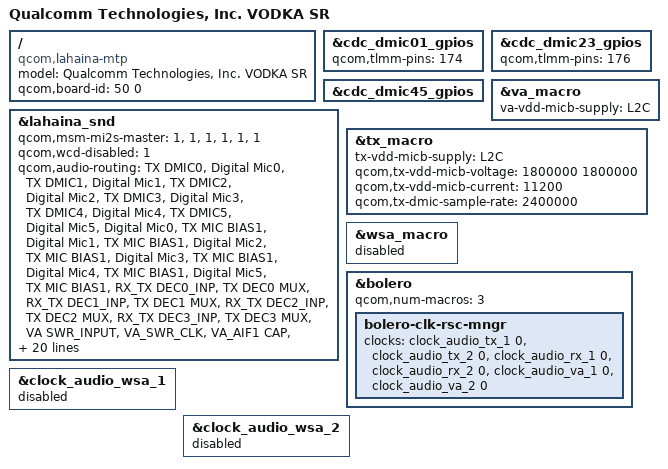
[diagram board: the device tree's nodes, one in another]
/dts-v1/;
/plugin/;

#include "VODKA-EVB2-overlay.dts"

/ {
	model = "Qualcomm Technologies, Inc. VODKA SR";
	compatible = "qcom,lahaina-mtp", "qcom,lahaina", "qcom,mtp";
	qcom,board-id = <50 0>;
};

/*   ====================================
*    overlay for display - start
*    ====================================
*/

/*   ====================================
*    overlay for display - end
*    ====================================
*/

/*    ====================================
 *    overlay for lahainap-v2.dtsi - start
 *    ====================================
 */

/*    ====================================
 *    overlay for lahainap-v2.dtsi - end
 *    ====================================
 */



/*    ====================================
 *    overlay for lahainap.dtsi - start
 *    ====================================
 */

/*    ====================================
 *    overlay for lahainap.dtsi - end
 *    ====================================
 */



/*    ====================================
 *    overlay for lahaina-mtp.dtsi - start
 *    ====================================
 */
 
 
/*    ====================================
 *    overlay for lahaina-mtp.dtsi - end
 *    ====================================
 */


/*    ====================================
 *    overlay for lahaina-pm.dtsi - start
 *    ====================================
 */

/*    ====================================
 *    overlay for lahaina-pm.dtsi - end
 *    ====================================
 */



/*    ====================================
 *    overlay for lahaina-pinctrl.dtsi - start
 *    ====================================
 */

/*    ====================================
 *    overlay for lahaina-pinctrl.dtsi - end
 *    ====================================
 */



/*    ====================================
 *    overlay for lahaina-pmic-overlay.dtsi - start
 *    ====================================
 */

/*    ====================================
 *    overlay for lahaina-pmic-overlay.dtsi - end
 *    ====================================
 */


/*    ====================================
 *    overlay for pm8350.dtsi - start
 *    ====================================
 */

/*    ====================================
 *    overlay for pm8350.dtsi - end
 *    ====================================
 */


/*    ====================================
 *    overlay for pmk8350.dtsi - start
 *    ====================================
 */

/*    ====================================
 *    overlay for pmk8350.dtsi - end
 *    ====================================
 */

/*    ====================================
 *    overlay for pm8350b.dtsi - start
 *    ====================================
 */

/*    ====================================
 *    overlay for pm8350b.dtsi - end
 *    ====================================
 */

/*    ====================================
 *    overlay for pm8350c.dtsi - start
 *    ====================================
 */

/*    ====================================
 *    overlay for pm8350c.dtsi - end
 *    ====================================
 */


/*    ====================================
 *    overlay for lahaina-regulators.dtsi - start
 *    ====================================
 */

/*    ====================================
 *    overlay for lahaina-regulators.dtsi - end
 *    ====================================
 */
  

 
/*    ====================================
 *    overlay for lahaina-audio.dtsi - start
 *    ====================================
 */

&cdc_dmic01_gpios {
	qcom,tlmm-pins = <174>;
};

&cdc_dmic23_gpios {
	qcom,tlmm-pins = <176>;
};

&cdc_dmic45_gpios {
	status = "ok";
};

&lahaina_snd {
	qcom,msm-mi2s-master = <1>, <1>, <1>, <1>, <1>, <1>;
	qcom,wcd-disabled = <1>;
	qcom,audio-routing =
		"TX DMIC0", "Digital Mic0",
		"TX DMIC1", "Digital Mic1",
		"TX DMIC2", "Digital Mic2",
		"TX DMIC3", "Digital Mic3",
		"TX DMIC4", "Digital Mic4",
		"TX DMIC5", "Digital Mic5",
		"Digital Mic0", "TX MIC BIAS1",
		"Digital Mic1", "TX MIC BIAS1",
		"Digital Mic2", "TX MIC BIAS1",
		"Digital Mic3", "TX MIC BIAS1",
		"Digital Mic4", "TX MIC BIAS1",
		"Digital Mic5", "TX MIC BIAS1",
		"RX_TX DEC0_INP", "TX DEC0 MUX",
		"RX_TX DEC1_INP", "TX DEC1 MUX",
		"RX_TX DEC2_INP", "TX DEC2 MUX",
		"RX_TX DEC3_INP", "TX DEC3 MUX",
		"VA SWR_INPUT", "VA_SWR_CLK",
		"VA_AIF1 CAP", "VA_SWR_CLK",
		"VA_AIF2 CAP", "VA_SWR_CLK",
		"VA_AIF3 CAP", "VA_SWR_CLK",
		"VA DMIC0", "Digital Mic0",
		"VA DMIC1", "Digital Mic1",
		"VA DMIC2", "Digital Mic2",
		"VA DMIC3", "Digital Mic3",
		"VA DMIC4", "Digital Mic4",
		"VA DMIC5", "Digital Mic5",
		"Digital Mic0", "VA MIC BIAS1",
		"Digital Mic1", "VA MIC BIAS1",
		"Digital Mic2", "VA MIC BIAS1",
		"Digital Mic3", "VA MIC BIAS1",
		"Digital Mic4", "VA MIC BIAS1",
		"Digital Mic5", "VA MIC BIAS1";
	qcom,msm-mbhc-hphl-swh;
	qcom,msm-mbhc-gnd-swh;
	qcom,cdc-dmic01-gpios = <&cdc_dmic01_gpios>;
	qcom,cdc-dmic23-gpios = <&cdc_dmic23_gpios>;
	qcom,cdc-dmic45-gpios = <&cdc_dmic45_gpios>;
	asoc-codec  = <&stub_codec>, <&bolero>,
		      <&ext_disp_audio_codec>;
	asoc-codec-names = "msm-stub-codec.1", "bolero_codec",
			   "msm-ext-disp-audio-codec-rx";
	qcom,wsa-max-devs;
};

&va_macro {
	va-vdd-micb-supply = <&L2C>;
};

&tx_macro {
	tx-vdd-micb-supply = <&L2C>;
	qcom,tx-vdd-micb-voltage = <1800000 1800000>;
	qcom,tx-vdd-micb-current = <11200>;
	qcom,tx-dmic-sample-rate = <2400000>;
};

&wsa_macro {
	status = "disabled";
};

&bolero {
	qcom,num-macros = <3>;
	bolero-clk-rsc-mngr {
		clock-names = "tx_core_clk", "tx_npl_clk", "rx_core_clk", "rx_npl_clk",
			 "va_core_clk", "va_npl_clk";
		clocks = <&clock_audio_tx_1 0>, <&clock_audio_tx_2 0>,
			<&clock_audio_rx_1 0>, <&clock_audio_rx_2 0>,
			<&clock_audio_va_1 0>, <&clock_audio_va_2 0>;
	};
};

&clock_audio_wsa_1 {
	status = "disabled";
};

&clock_audio_wsa_2 {
	status = "disabled";
};

/*    ====================================
 *    overlay for lahaina-audio.dtsi - end
 *    ====================================
 */

/*    ====================================
 *    overlay for lahaina-audio-overlay.dtsi - start
 *    ====================================
 */

/*    ====================================
 *    overlay for lahaina-audio-overlay.dtsi - end
 *    ====================================
 */


/*    ====================================
 *    overlay for lahaina-thermal-overlay.dtsi - start
 *    ====================================
 */

/*    ====================================
 *    overlay for lahaina-thermal-overlay.dtsi - end
 *    ====================================
 */

 
/*    ====================================
 *    overlay for lahaina-gpu.dtsi - start
 *    ====================================
 */

/*    ====================================
 *    overlay for lahaina-gpu.dtsi - end
 *    ====================================
 */


/*    ====================================
 *    overlay for lahaina-usb.dtsi - start
 *    ====================================
 */

/*    ====================================
 *    overlay for lahaina-usb.dtsi - end
 *    ====================================
 */
 
